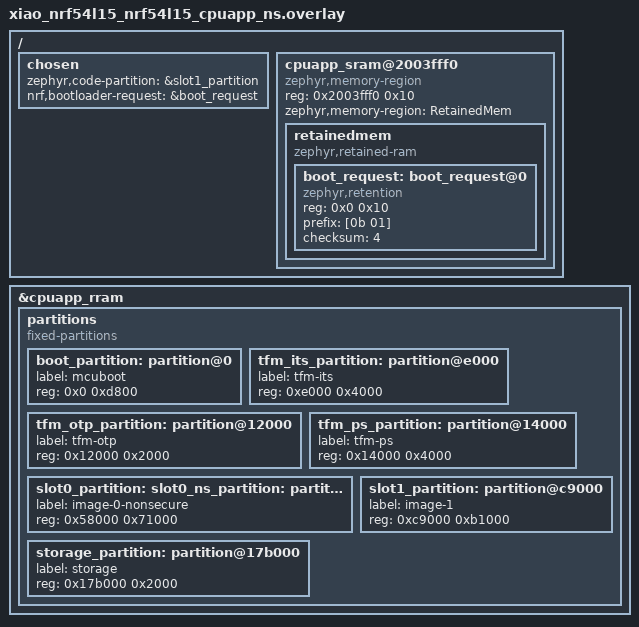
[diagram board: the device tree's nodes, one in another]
/*
 * Copyright (c) 2026
 *
 * SPDX-License-Identifier: LicenseRef-Nordic-5-Clause
 */

/ {
	chosen {
		zephyr,code-partition = &slot1_partition;
		nrf,bootloader-request = &boot_request;
	};

	cpuapp_sram@2003fff0 {
		compatible = "zephyr,memory-region", "mmio-sram";
		reg = <0x2003fff0 0x10>;
		zephyr,memory-region = "RetainedMem";
		status = "okay";

		retainedmem {
			compatible = "zephyr,retained-ram";
			status = "okay";
			#address-cells = <1>;
			#size-cells = <1>;

			boot_request: boot_request@0 {
				compatible = "zephyr,retention";
				status = "okay";
				reg = <0x0 0x10>;
				prefix = [0b 01];
				checksum = <4>;
			};
		};
	};
};

&cpuapp_rram {
	/delete-node/ partitions;

	partitions {
		compatible = "fixed-partitions";
		#address-cells = <1>;
		#size-cells = <1>;

		boot_partition: partition@0 {
			label = "mcuboot";
			reg = <0x0 0xd800>;
		};

		tfm_its_partition: partition@e000 {
			label = "tfm-its";
			reg = <0xe000 0x4000>;
		};

		tfm_otp_partition: partition@12000 {
			label = "tfm-otp";
			reg = <0x12000 0x2000>;
		};

		tfm_ps_partition: partition@14000 {
			label = "tfm-ps";
			reg = <0x14000 0x4000>;
		};

		slot0_partition: slot0_ns_partition: partition@58000 {
			label = "image-0-nonsecure";
			reg = <0x58000 0x71000>;
		};

		slot1_partition: partition@c9000 {
			label = "image-1";
			reg = <0xc9000 0xb1000>;
		};

		storage_partition: partition@17b000 {
			label = "storage";
			reg = <0x17b000 0x2000>;
		};
	};
};
